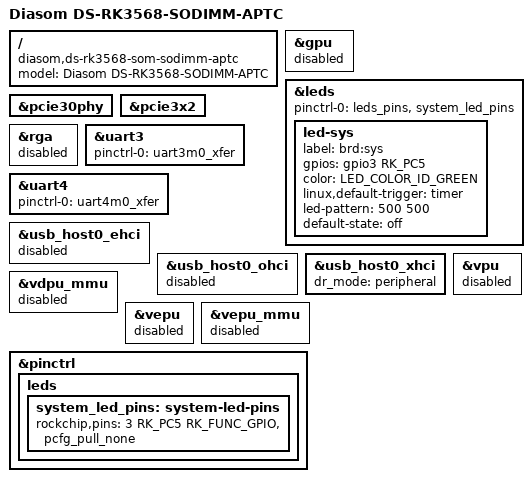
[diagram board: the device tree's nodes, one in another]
/* SPDX-License-Identifier: GPL-2.0+ */
/* SPDX-FileCopyrightText: Alexander Shiyan <shc_work@mail.ru> */

/dts-v1/;

#include "rk3568-diasom-som-sodimm.dtsi"

/ {
	model = "Diasom DS-RK3568-SODIMM-APTC";
	compatible = "diasom,ds-rk3568-som-sodimm-aptc",
		     "diasom,ds-rk3568-som-sodimm",
		     "diasom,ds-rk3568-som",
		     "rockchip,rk3568";
};

&gpu {
	status = "disabled";
};

&leds {
	pinctrl-0 = <&leds_pins &system_led_pins>;

	led-sys {
		label = "brd:sys";
		gpios = <&gpio3 RK_PC5 GPIO_ACTIVE_HIGH>;
		color = <LED_COLOR_ID_GREEN>;
		linux,default-trigger = "timer";
		led-pattern = <500 500>;
		default-state = "off";
	};
};

&pcie30phy {
	status = "okay";
};

&pcie3x2 {
	status = "okay";
};

&rga {
	status = "disabled";
};

&uart3 {
	/* UART1 */
	pinctrl-0 = <&uart3m0_xfer>;
	status = "okay";
};

&uart4 {
	/* UART0 */
	pinctrl-0 = <&uart4m0_xfer>;
	status = "okay";
};

&usb_host0_ehci {
	status = "disabled";
};

&usb_host0_ohci {
	status = "disabled";
};

&usb_host0_xhci {
	dr_mode = "peripheral";
};

&vpu {
	status = "disabled";
};

&vdpu_mmu {
	status = "disabled";
};

&vepu {
	status = "disabled";
};

&vepu_mmu {
	status = "disabled";
};

&pinctrl {
	leds {
		system_led_pins: system-led-pins {
			rockchip,pins =
				<3 RK_PC5 RK_FUNC_GPIO &pcfg_pull_none>;	/* SYSTEM_LED */
		};
	};
};
